VERSION "HSCAN2"

NS_ :

BS_:

BU_: FVCM Diagnostics GW EPS EHBS SCSABS Tester vector__xxx

BO_ 1947 DIAG_DTCInfo_FVCM: 7 FVCM
 SG_ DTCInfomationFVCMHSC2 : 7|56@0+ (1,0) [0|0] ""  vector__xxx

BO_ 1851 DIAG_PhysResp_FVCM: 8 FVCM
 SG_ DiagnosticRespFVCM : 7|64@0+ (1,0) [0|0] ""  Diagnostics

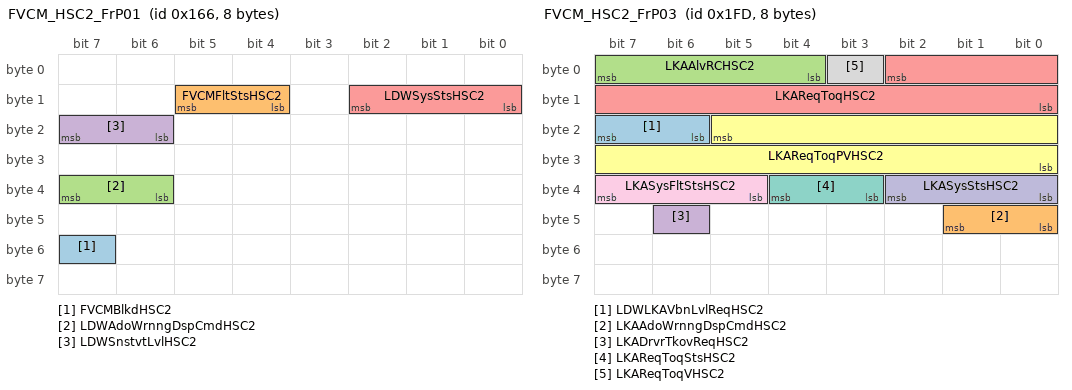
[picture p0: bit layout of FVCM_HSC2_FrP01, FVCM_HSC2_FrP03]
BO_ 358 FVCM_HSC2_FrP01: 8 FVCM
 SG_ FVCMBlkdHSC2 : 55|1@0+ (1,0) [0|1] ""  GW
 SG_ FVCMFltStsHSC2 : 13|2@0+ (1,0) [0|3] ""  GW,EPS
 SG_ LDWAdoWrnngDspCmdHSC2 : 39|2@0+ (1,0) [0|3] ""  GW
 SG_ LDWSnstvtLvlHSC2 : 23|2@0+ (1,0) [0|3] ""  GW
 SG_ LDWSysStsHSC2 : 10|3@0+ (1,0) [0|7] ""  GW

BO_ 359 FVCM_HSC2_FrP02: 8 FVCM
 SG_ AutoMainBeamLghtReqHSC2 : 15|2@0+ (1,0) [0|3] ""  GW
 SG_ DistSinceTrgtCamrHSC2 : 7|8@0+ (8.235,-100) [-100|1999.92] ""  GW
 SG_ FVCMCalPrgsReqHSC2 : 36|3@0+ (1,0) [0|7] ""  GW
 SG_ HandOffStrgWhlDetnStaHSC2 : 44|2@0+ (1,0) [0|3] ""  GW
 SG_ HandOffStrgWhlDetnStaVHSC2 : 45|1@0+ (1,0) [0|1] ""  GW
 SG_ LDWLKAAudReqHSC2 : 47|2@0+ (1,0) [0|3] ""  GW
 SG_ LDWLKADspCmdHSC2 : 50|3@0+ (1,0) [0|7] ""  GW
 SG_ LDWLKAHapticWrnngDspCmdHSC2 : 63|2@0+ (1,0) [0|3] ""  GW
 SG_ LDWLKALVsulznReqHSC2 : 53|3@0+ (1,0) [0|7] ""  GW
 SG_ LDWLKARVsulznReqHSC2 : 42|3@0+ (1,0) [0|7] ""  GW
 SG_ LDWSysFltStsHSC2 : 39|3@0+ (1,0) [0|7] ""  GW
 SG_ SpdAstCondStsCamrHSC2 : 11|4@0+ (1,0) [0|15] ""  GW
 SG_ SpdAstReqStsCamrHSC2 : 13|2@0+ (1,0) [0|3] ""  GW
 SG_ TJAICADspCmdHSC2 : 55|2@0+ (1,0) [0|3] ""  GW
 SG_ TJAICASysFltStsHSC2 : 61|3@0+ (1,0) [0|7] ""  GW,EPS
 SG_ TJAICASysStsHSC2 : 58|3@0+ (1,0) [0|7] ""  GW,EPS
 SG_ TrgtSpdReqCamrHSC2 : 22|15@0+ (0.015625,0) [0|511.984] ""  GW

BO_ 509 FVCM_HSC2_FrP03: 8 FVCM
 SG_ LDWLKAVbnLvlReqHSC2 : 23|2@0+ (1,0) [0|3] ""  GW,EPS
 SG_ LKAAdoWrnngDspCmdHSC2 : 41|2@0+ (1,0) [0|3] ""  vector__xxx
 SG_ LKAAlvRCHSC2 : 7|4@0+ (1,0) [0|15] ""  EPS
 SG_ LKADrvrTkovReqHSC2 : 46|1@0+ (1,0) [0|1] ""  GW
 SG_ LKAReqToqHSC2 : 2|11@0+ (0.01,-10.24) [-10.24|10.23] ""  EPS
 SG_ LKAReqToqPVHSC2 : 21|14@0+ (1,0) [0|16383] ""  EPS
 SG_ LKAReqToqStsHSC2 : 36|2@0+ (1,0) [0|3] ""  EPS
 SG_ LKAReqToqVHSC2 : 3|1@0+ (1,0) [0|1] ""  EPS
 SG_ LKASysFltStsHSC2 : 39|3@0+ (1,0) [0|7] ""  GW,EPS
 SG_ LKASysStsHSC2 : 34|3@0+ (1,0) [0|7] ""  GW,EPS

BO_ 2015 DIAG_FuncReq_HSC2: 8 Diagnostics
 SG_ DiagnosticFuncAddrReq_h2 : 7|64@0+ (1,0) [0|0] ""  FVCM

BO_ 1843 DIAG_PhysReq_FVCM: 8 Diagnostics
 SG_ DiagnosticReqFVCM_h2 : 7|64@0+ (1,0) [0|0] ""  FVCM

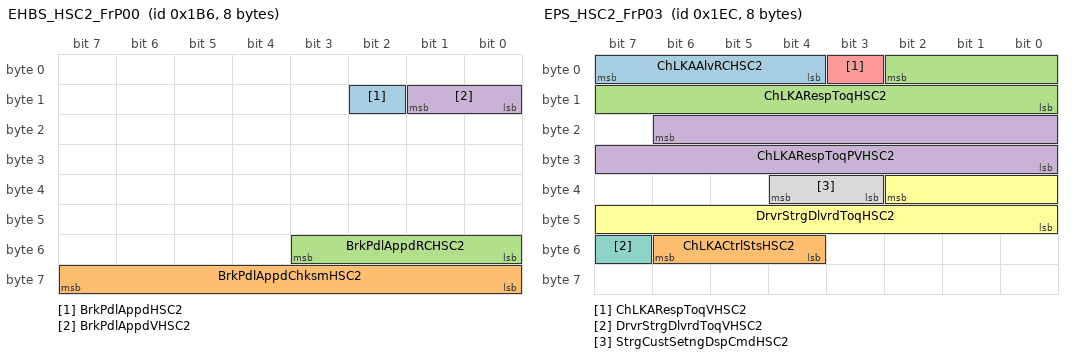
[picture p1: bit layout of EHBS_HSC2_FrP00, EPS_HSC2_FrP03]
BO_ 438 EHBS_HSC2_FrP00: 8 EHBS
 SG_ BrkPdlAppdHSC2 : 10|1@0+ (1,0) [0|1] ""  FVCM
 SG_ BrkPdlAppdChksmHSC2 : 63|8@0+ (1,0) [0|255] ""  FVCM
 SG_ BrkPdlAppdRCHSC2 : 51|4@0+ (1,0) [0|15] ""  FVCM
 SG_ BrkPdlAppdVHSC2 : 9|2@0+ (1,0) [0|3] ""  FVCM

BO_ 492 EPS_HSC2_FrP03: 8 EPS
 SG_ ChLKAAlvRCHSC2 : 7|4@0+ (1,0) [0|15] ""  FVCM
 SG_ ChLKACtrlStsHSC2 : 54|3@0+ (1,0) [0|7] ""  FVCM
 SG_ ChLKARespToqHSC2 : 2|11@0+ (0.01,-10.24) [-10.24|10.23] ""  FVCM
 SG_ ChLKARespToqPVHSC2 : 22|15@0+ (1,0) [0|32767] ""  FVCM
 SG_ ChLKARespToqVHSC2 : 3|1@0+ (1,0) [0|1] ""  FVCM
 SG_ DrvrStrgDlvrdToqHSC2 : 34|11@0+ (0.01,-10.24) [-10.24|10.23] ""  FVCM
 SG_ DrvrStrgDlvrdToqVHSC2 : 55|1@0+ (1,0) [0|1] ""  FVCM
 SG_ StrgCustSetngDspCmdHSC2 : 36|2@0+ (1,0) [0|3] ""  FVCM

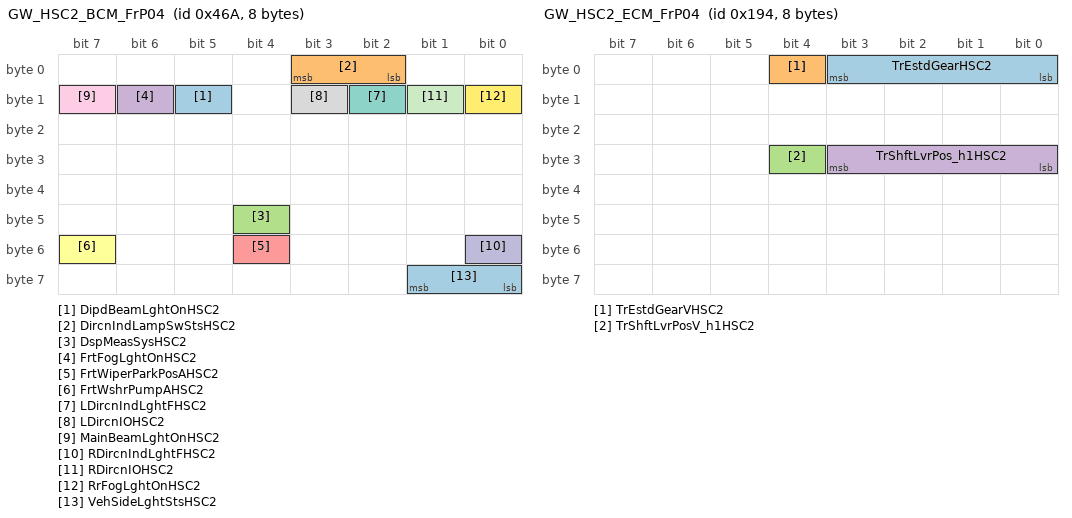
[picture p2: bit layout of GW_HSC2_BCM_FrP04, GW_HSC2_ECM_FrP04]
BO_ 1130 GW_HSC2_BCM_FrP04: 8 GW
 SG_ DipdBeamLghtOnHSC2 : 13|1@0+ (1,0) [0|1] ""  FVCM
 SG_ DircnIndLampSwStsHSC2 : 3|2@0+ (1,0) [0|3] ""  FVCM
 SG_ DspMeasSysHSC2 : 44|1@0+ (1,0) [0|1] ""  FVCM
 SG_ FrtFogLghtOnHSC2 : 14|1@0+ (1,0) [0|1] ""  FVCM
 SG_ FrtWiperParkPosAHSC2 : 52|1@0+ (1,0) [0|1] ""  FVCM
 SG_ FrtWshrPumpAHSC2 : 55|1@0+ (1,0) [0|1] ""  FVCM
 SG_ LDircnIndLghtFHSC2 : 10|1@0+ (1,0) [0|1] ""  FVCM
 SG_ LDircnIOHSC2 : 11|1@0+ (1,0) [0|1] ""  FVCM
 SG_ MainBeamLghtOnHSC2 : 15|1@0+ (1,0) [0|1] ""  FVCM
 SG_ RDircnIndLghtFHSC2 : 48|1@0+ (1,0) [0|1] ""  FVCM
 SG_ RDircnIOHSC2 : 9|1@0+ (1,0) [0|1] ""  FVCM
 SG_ RrFogLghtOnHSC2 : 8|1@0+ (1,0) [0|1] ""  FVCM
 SG_ VehSideLghtStsHSC2 : 57|2@0+ (1,0) [0|3] ""  FVCM

BO_ 540 GW_HSC2_BCM_FrP06: 8 GW
 SG_ ClstrDspdVehSpdHSC2 : 55|8@0+ (1,0) [0|254] ""  FVCM
 SG_ FrtWiperSwStsHSC2 : 47|2@0+ (1,0) [0|3] ""  FVCM

BO_ 498 GW_HSC2_BCM_FrP07: 2 GW
 SG_ SysBPMHSC2 : 5|2@0+ (1,0) [0|3] ""  FVCM
 SG_ SysBPMEnbdHSC2 : 6|1@0+ (1,0) [0|1] ""  FVCM

BO_ 404 GW_HSC2_ECM_FrP04: 8 GW
 SG_ TrEstdGearHSC2 : 3|4@0+ (1,0) [0|15] ""  FVCM
 SG_ TrEstdGearVHSC2 : 4|1@0+ (1,0) [0|1] ""  FVCM
 SG_ TrShftLvrPosV_h1HSC2 : 28|1@0+ (1,0) [0|1] ""  FVCM
 SG_ TrShftLvrPos_h1HSC2 : 27|4@0+ (1,0) [0|15] ""  FVCM

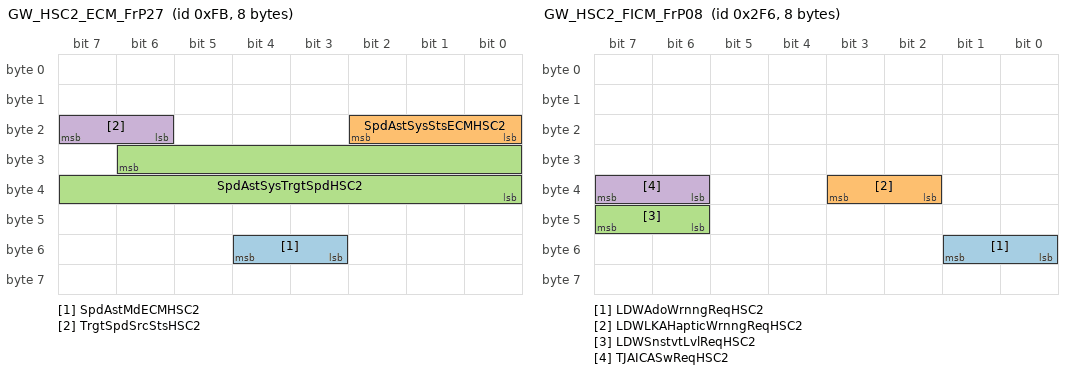
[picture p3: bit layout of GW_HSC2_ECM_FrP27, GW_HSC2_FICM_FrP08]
BO_ 251 GW_HSC2_ECM_FrP27: 8 GW
 SG_ SpdAstMdECMHSC2 : 52|2@0+ (1,0) [0|3] ""  FVCM
 SG_ SpdAstSysStsECMHSC2 : 18|3@0+ (1,0) [0|7] ""  FVCM
 SG_ SpdAstSysTrgtSpdHSC2 : 30|15@0+ (0.015625,0) [0|511.984] ""  FVCM
 SG_ TrgtSpdSrcStsHSC2 : 23|2@0+ (1,0) [0|3] ""  FVCM

BO_ 886 GW_HSC2_FICM_FrP02: 8 GW
 SG_ LDWLKASwReqHSC2 : 31|3@0+ (1,0) [0|7] ""  FVCM
 SG_ RstrFctryDeftsReqHSC2 : 56|1@0+ (1,0) [0|1] ""  FVCM

BO_ 758 GW_HSC2_FICM_FrP08: 8 GW
 SG_ LDWAdoWrnngReqHSC2 : 49|2@0+ (1,0) [0|3] ""  FVCM
 SG_ LDWLKAHapticWrnngReqHSC2 : 35|2@0+ (1,0) [0|3] ""  FVCM
 SG_ LDWSnstvtLvlReqHSC2 : 47|2@0+ (1,0) [0|3] ""  FVCM
 SG_ TJAICASwReqHSC2 : 39|2@0+ (1,0) [0|3] ""  FVCM

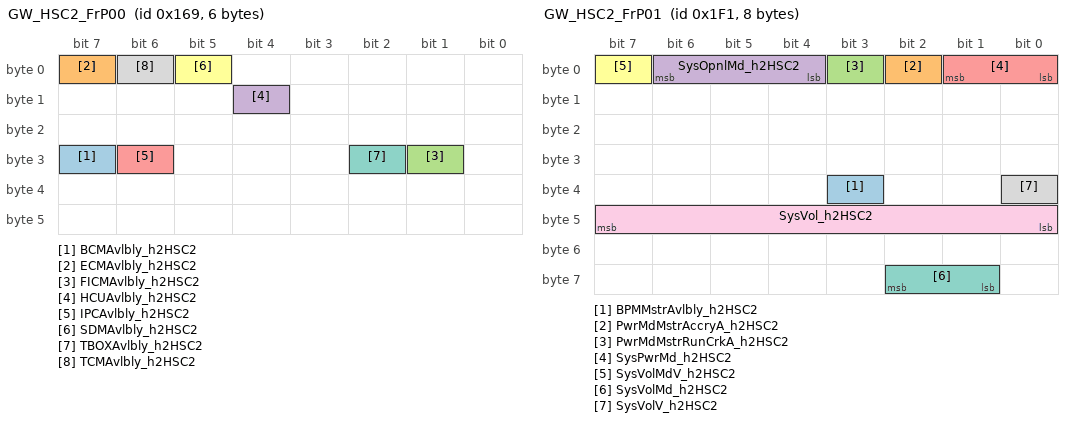
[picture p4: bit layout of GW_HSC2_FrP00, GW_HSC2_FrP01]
BO_ 361 GW_HSC2_FrP00: 6 GW
 SG_ BCMAvlbly_h2HSC2 : 31|1@0+ (1,0) [0|1] ""  FVCM
 SG_ ECMAvlbly_h2HSC2 : 7|1@0+ (1,0) [0|1] ""  FVCM
 SG_ FICMAvlbly_h2HSC2 : 25|1@0+ (1,0) [0|1] ""  FVCM
 SG_ HCUAvlbly_h2HSC2 : 12|1@0+ (1,0) [0|1] ""  FVCM
 SG_ IPCAvlbly_h2HSC2 : 30|1@0+ (1,0) [0|1] ""  FVCM
 SG_ SDMAvlbly_h2HSC2 : 5|1@0+ (1,0) [0|1] ""  FVCM
 SG_ TBOXAvlbly_h2HSC2 : 26|1@0+ (1,0) [0|1] ""  FVCM
 SG_ TCMAvlbly_h2HSC2 : 6|1@0+ (1,0) [0|1] ""  FVCM

BO_ 497 GW_HSC2_FrP01: 8 GW
 SG_ BPMMstrAvlbly_h2HSC2 : 35|1@0+ (1,0) [0|1] ""  FVCM
 SG_ PwrMdMstrAccryA_h2HSC2 : 2|1@0+ (1,0) [0|1] ""  FVCM
 SG_ PwrMdMstrRunCrkA_h2HSC2 : 3|1@0+ (1,0) [0|1] ""  FVCM
 SG_ SysOpnlMd_h2HSC2 : 6|3@0+ (1,0) [0|7] ""  FVCM
 SG_ SysPwrMd_h2HSC2 : 1|2@0+ (1,0) [0|3] ""  FVCM
 SG_ SysVolMdV_h2HSC2 : 7|1@0+ (1,0) [0|1] ""  FVCM
 SG_ SysVolMd_h2HSC2 : 58|2@0+ (1,0) [0|3] ""  FVCM
 SG_ SysVolV_h2HSC2 : 32|1@0+ (1,0) [0|1] ""  FVCM
 SG_ SysVol_h2HSC2 : 47|8@0+ (0.1,3) [3|28.5] ""  FVCM

BO_ 1344 GW_HSC2_FrP08: 8 GW
 SG_ VehOdoV_h2HSC2 : 31|1@0+ (1,0) [0|1] ""  FVCM
 SG_ VehOdo_h2HSC2 : 7|24@0+ (1,0) [0|16777200] ""  FVCM

BO_ 795 GW_HSC2_FrP09: 8 GW
 SG_ LKASwAHSC2 : 57|2@0+ (1,0) [0|3] ""  FVCM
 SG_ VehDrvngMd_h2HSC2 : 29|3@0+ (1,0) [0|7] ""  FVCM

BO_ 1009 GW_HSC2_FrP10: 8 GW
 SG_ OtsdAirTemCrValV_h2HSC2 : 48|1@0+ (1,0) [0|1] ""  FVCM
 SG_ OtsdAirTemCrVal_h2HSC2 : 63|8@0+ (0.5,-40) [-40|87.5] ""  FVCM

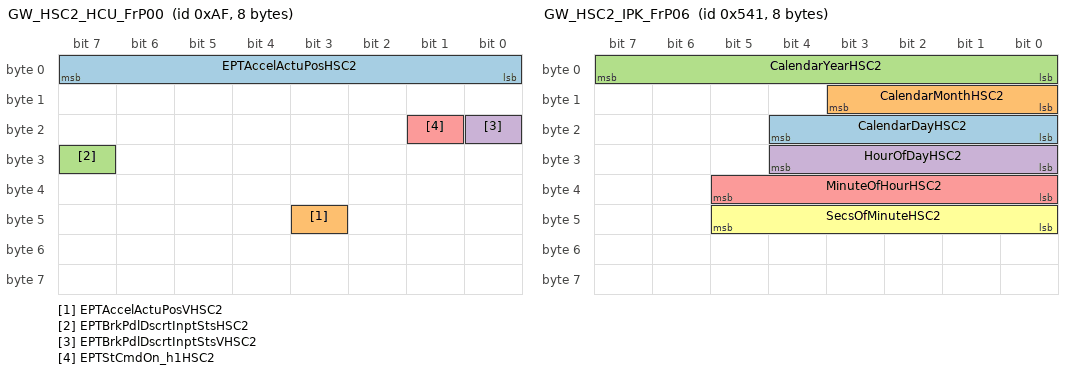
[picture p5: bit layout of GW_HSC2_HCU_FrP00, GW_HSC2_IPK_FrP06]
BO_ 175 GW_HSC2_HCU_FrP00: 8 GW
 SG_ EPTAccelActuPosHSC2 : 7|8@0+ (0.392157,0) [0|100] ""  FVCM
 SG_ EPTAccelActuPosVHSC2 : 43|1@0+ (1,0) [0|1] ""  FVCM
 SG_ EPTBrkPdlDscrtInptStsHSC2 : 31|1@0+ (1,0) [0|1] ""  FVCM
 SG_ EPTBrkPdlDscrtInptStsVHSC2 : 16|1@0+ (1,0) [0|1] ""  FVCM
 SG_ EPTStCmdOn_h1HSC2 : 17|1@0+ (1,0) [0|1] ""  FVCM

BO_ 406 GW_HSC2_HCU_FrP01: 8 GW
 SG_ EPTAccelEfctvPosHSC2 : 47|8@0+ (0.392157,0) [0|100] ""  FVCM
 SG_ EPTRdy_h1HSC2 : 38|1@0+ (1,0) [0|1] ""  FVCM

BO_ 172 GW_HSC2_HCU_FrP08: 8 GW
 SG_ SLIFStsHSC2 : 35|3@0+ (1,0) [0|7] ""  FVCM

BO_ 1345 GW_HSC2_IPK_FrP06: 8 GW
 SG_ CalendarDayHSC2 : 20|5@0+ (1,0) [0|31] ""  FVCM
 SG_ CalendarMonthHSC2 : 11|4@0+ (1,0) [0|15] ""  FVCM
 SG_ CalendarYearHSC2 : 7|8@0+ (1,2000) [2000|2255] ""  FVCM
 SG_ HourOfDayHSC2 : 28|5@0+ (1,0) [0|23] ""  FVCM
 SG_ MinuteOfHourHSC2 : 37|6@0+ (1,0) [0|59] ""  FVCM
 SG_ SecsOfMinuteHSC2 : 45|6@0+ (1,0) [0|59] ""  FVCM

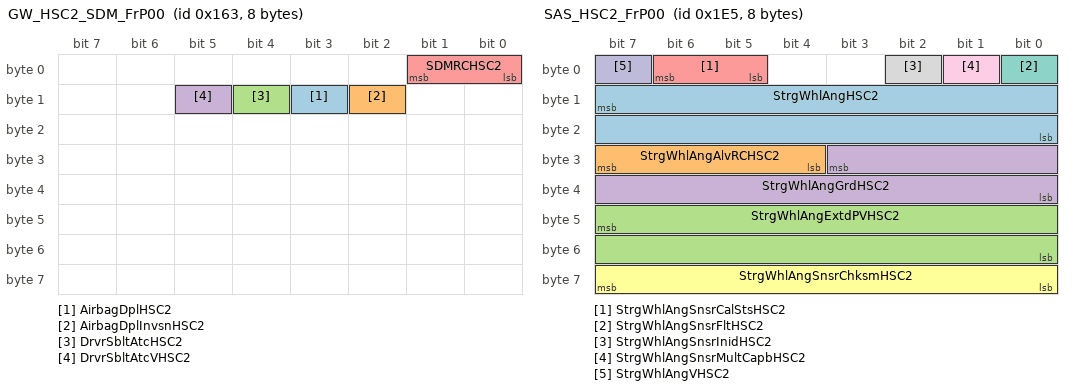
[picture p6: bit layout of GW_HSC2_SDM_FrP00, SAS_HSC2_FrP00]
BO_ 355 GW_HSC2_SDM_FrP00: 8 GW
 SG_ AirbagDplHSC2 : 11|1@0+ (1,0) [0|1] ""  FVCM
 SG_ AirbagDplInvsnHSC2 : 10|1@0+ (1,0) [0|1] ""  FVCM
 SG_ DrvrSbltAtcHSC2 : 12|1@0+ (1,0) [0|1] ""  FVCM
 SG_ DrvrSbltAtcVHSC2 : 13|1@0+ (1,0) [0|1] ""  FVCM
 SG_ SDMRCHSC2 : 1|2@0+ (1,0) [0|3] ""  FVCM

BO_ 485 SAS_HSC2_FrP00: 8 EPS
 SG_ StrgWhlAngHSC2 : 15|16@0+ (0.0625,-2048) [-2048|2047.88] ""  FVCM
 SG_ StrgWhlAngAlvRCHSC2 : 31|4@0+ (1,0) [0|15] ""  FVCM
 SG_ StrgWhlAngExtdPVHSC2 : 47|16@0+ (1,0) [0|65535] ""  FVCM
 SG_ StrgWhlAngGrdHSC2 : 27|12@0+ (1,-2048) [-2048|2046] ""  FVCM
 SG_ StrgWhlAngSnsrCalStsHSC2 : 6|2@0+ (1,0) [0|3] ""  FVCM
 SG_ StrgWhlAngSnsrChksmHSC2 : 63|8@0+ (1,0) [0|255] ""  FVCM
 SG_ StrgWhlAngSnsrFltHSC2 : 0|1@0+ (1,0) [0|1] ""  FVCM
 SG_ StrgWhlAngSnsrInidHSC2 : 2|1@0+ (1,0) [0|1] ""  FVCM
 SG_ StrgWhlAngSnsrMultCapbHSC2 : 1|1@0+ (1,0) [0|1] ""  FVCM
 SG_ StrgWhlAngVHSC2 : 7|1@0+ (1,0) [0|1] ""  FVCM

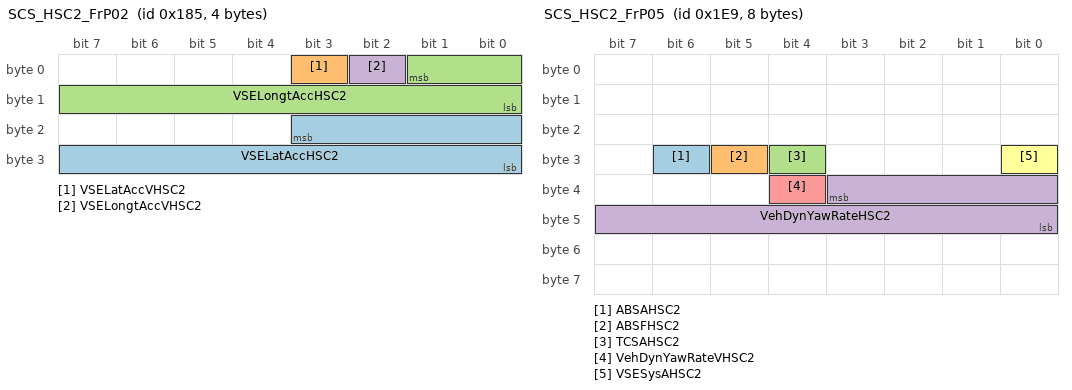
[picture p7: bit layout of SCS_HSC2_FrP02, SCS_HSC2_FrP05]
BO_ 389 SCS_HSC2_FrP02: 4 SCSABS
 SG_ VSELatAccHSC2 : 19|12@0- (0.015625,0) [-32|31.9844] ""  FVCM
 SG_ VSELatAccVHSC2 : 3|1@0+ (1,0) [0|1] ""  FVCM
 SG_ VSELongtAccHSC2 : 1|10@0- (0.03,0) [-15.36|15.33] ""  FVCM
 SG_ VSELongtAccVHSC2 : 2|1@0+ (1,0) [0|1] ""  FVCM

BO_ 455 SCS_HSC2_FrP03: 8 SCSABS
 SG_ LNonDrvnWhlRotlDircnHSC2 : 33|2@0+ (1,0) [0|3] ""  FVCM
 SG_ RNonDrvnWhlRotlDircnHSC2 : 35|2@0+ (1,0) [0|3] ""  FVCM

BO_ 489 SCS_HSC2_FrP05: 8 SCSABS
 SG_ ABSAHSC2 : 30|1@0+ (1,0) [0|1] ""  FVCM
 SG_ ABSFHSC2 : 29|1@0+ (1,0) [0|1] ""  FVCM
 SG_ TCSAHSC2 : 28|1@0+ (1,0) [0|1] ""  FVCM
 SG_ VehDynYawRateHSC2 : 35|12@0- (0.0625,0) [-128|127.938] ""  FVCM
 SG_ VehDynYawRateVHSC2 : 36|1@0+ (1,0) [0|1] ""  FVCM
 SG_ VSESysAHSC2 : 24|1@0+ (1,0) [0|1] ""  FVCM

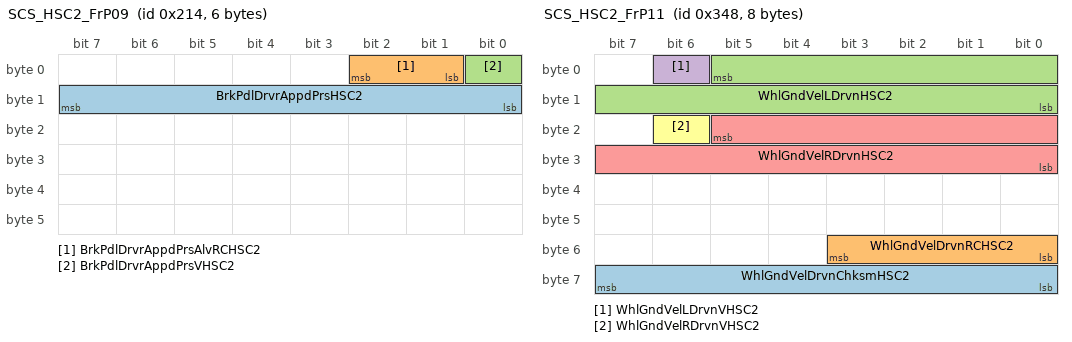
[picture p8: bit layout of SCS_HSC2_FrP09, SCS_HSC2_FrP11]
BO_ 532 SCS_HSC2_FrP09: 6 SCSABS
 SG_ BrkPdlDrvrAppdPrsHSC2 : 15|8@0+ (75,0) [0|19125] ""  FVCM
 SG_ BrkPdlDrvrAppdPrsAlvRCHSC2 : 2|2@0+ (1,0) [0|3] ""  FVCM
 SG_ BrkPdlDrvrAppdPrsVHSC2 : 0|1@0+ (1,0) [0|1] ""  FVCM

BO_ 840 SCS_HSC2_FrP11: 8 SCSABS
 SG_ WhlGndVelDrvnChksmHSC2 : 63|8@0+ (1,0) [0|255] ""  FVCM
 SG_ WhlGndVelDrvnRCHSC2 : 51|4@0+ (1,0) [0|15] ""  FVCM
 SG_ WhlGndVelLDrvnHSC2 : 5|14@0+ (0.03125,0) [0|511.969] ""  FVCM
 SG_ WhlGndVelLDrvnVHSC2 : 6|1@0+ (1,0) [0|1] ""  FVCM
 SG_ WhlGndVelRDrvnHSC2 : 21|14@0+ (0.03125,0) [0|511.969] ""  FVCM
 SG_ WhlGndVelRDrvnVHSC2 : 22|1@0+ (1,0) [0|1] ""  FVCM

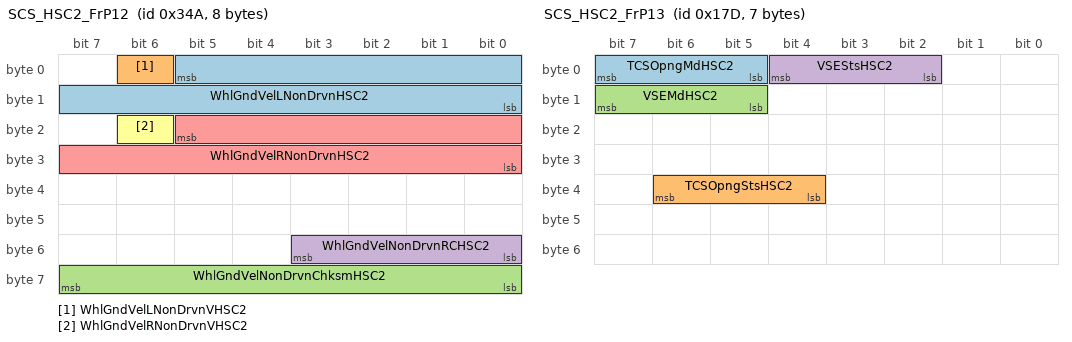
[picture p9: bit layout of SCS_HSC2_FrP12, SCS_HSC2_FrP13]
BO_ 842 SCS_HSC2_FrP12: 8 SCSABS
 SG_ WhlGndVelLNonDrvnHSC2 : 5|14@0+ (0.03125,0) [0|511.969] ""  FVCM
 SG_ WhlGndVelLNonDrvnVHSC2 : 6|1@0+ (1,0) [0|1] ""  FVCM
 SG_ WhlGndVelNonDrvnChksmHSC2 : 63|8@0+ (1,0) [0|255] ""  FVCM
 SG_ WhlGndVelNonDrvnRCHSC2 : 51|4@0+ (1,0) [0|15] ""  FVCM
 SG_ WhlGndVelRNonDrvnHSC2 : 21|14@0+ (0.03125,0) [0|511.969] ""  FVCM
 SG_ WhlGndVelRNonDrvnVHSC2 : 22|1@0+ (1,0) [0|1] ""  FVCM

BO_ 381 SCS_HSC2_FrP13: 7 SCSABS
 SG_ TCSOpngMdHSC2 : 7|3@0+ (1,0) [0|7] ""  FVCM
 SG_ TCSOpngStsHSC2 : 38|3@0+ (1,0) [0|7] ""  FVCM
 SG_ VSEMdHSC2 : 15|3@0+ (1,0) [0|7] ""  FVCM
 SG_ VSEStsHSC2 : 4|3@0+ (1,0) [0|7] ""  FVCM

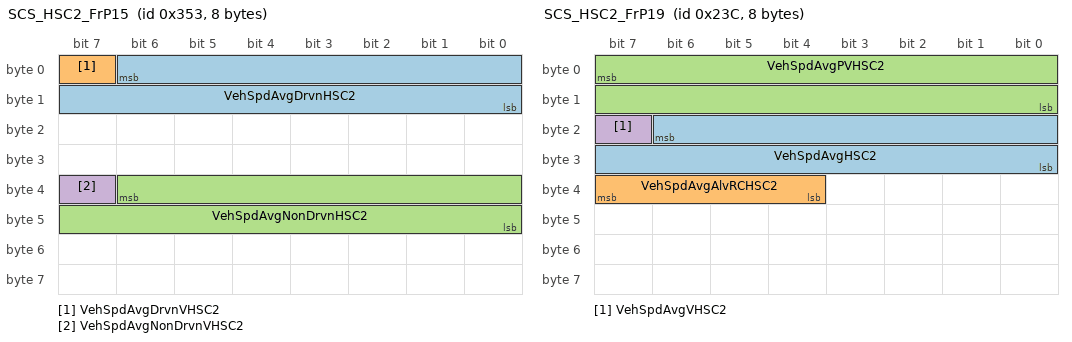
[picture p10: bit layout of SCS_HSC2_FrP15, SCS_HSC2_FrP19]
BO_ 851 SCS_HSC2_FrP15: 8 SCSABS
 SG_ VehSpdAvgDrvnHSC2 : 6|15@0+ (0.015625,0) [0|511.984] ""  FVCM
 SG_ VehSpdAvgDrvnVHSC2 : 7|1@0+ (1,0) [0|1] ""  FVCM
 SG_ VehSpdAvgNonDrvnHSC2 : 38|15@0+ (0.015625,0) [0|511.984] ""  FVCM
 SG_ VehSpdAvgNonDrvnVHSC2 : 39|1@0+ (1,0) [0|1] ""  FVCM

BO_ 572 SCS_HSC2_FrP19: 8 SCSABS
 SG_ VehSpdAvgHSC2 : 22|15@0+ (0.015625,0) [0|511.984] ""  FVCM
 SG_ VehSpdAvgAlvRCHSC2 : 39|4@0+ (1,0) [0|15] ""  FVCM
 SG_ VehSpdAvgPVHSC2 : 7|16@0+ (1,0) [0|65535] ""  FVCM
 SG_ VehSpdAvgVHSC2 : 23|1@0+ (1,0) [0|1] ""  FVCM

BO_ 588 SCS_HSC2_FrP22: 8 SCSABS
 SG_ LDrvnWhlRotlDircnHSC2 : 15|2@0+ (1,0) [0|3] ""  FVCM
 SG_ RDrvnWhlRotlDircnHSC2 : 2|2@0+ (1,0) [0|3] ""  FVCM

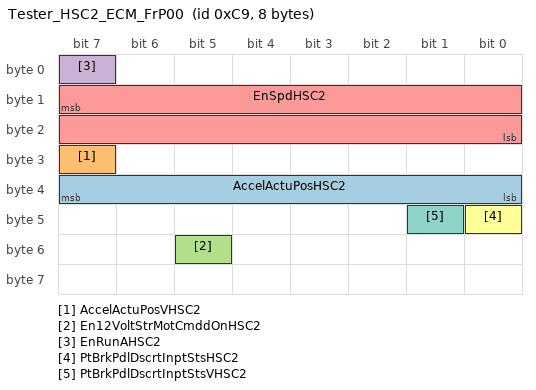
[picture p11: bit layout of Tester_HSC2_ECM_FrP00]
BO_ 201 Tester_HSC2_ECM_FrP00: 8 Tester
 SG_ AccelActuPosHSC2 : 39|8@0+ (0.392157,0) [0|100] ""  FVCM
 SG_ AccelActuPosVHSC2 : 31|1@0+ (1,0) [0|1] ""  FVCM
 SG_ En12VoltStrMotCmddOnHSC2 : 53|1@0+ (1,0) [0|1] ""  FVCM
 SG_ EnRunAHSC2 : 7|1@0+ (1,0) [0|1] ""  FVCM
 SG_ EnSpdHSC2 : 15|16@0+ (0.25,0) [0|16383.8] ""  FVCM
 SG_ PtBrkPdlDscrtInptStsHSC2 : 40|1@0+ (1,0) [0|1] ""  FVCM
 SG_ PtBrkPdlDscrtInptStsVHSC2 : 41|1@0+ (1,0) [0|1] ""  FVCM

BO_ 190 Tester_HSC2_ECM_FrP01: 3 Tester
 SG_ AccelEfctvPosHSC2 : 23|8@0+ (0.392157,0) [0|100] ""  FVCM

BO_ 471 Tester_HSC2_ECM_FrP07: 2 Tester
 SG_ EnASSStaHSC2 : 1|2@0+ (1,0) [0|3] ""  FVCM

CM_ SG_ 1947 DTCInfomationFVCMHSC2 "DTC Infomation of FVCM

The length of DTC information signal is 7 bytes.
Byte 0 is MSB (most significant byte), and Byte 6 is LSB (least significant byte).
For each byte, Bit 7 is msb (most significant bit), and Bit 0 is lsb (least significant bit).

Byte 0:
Bit (7-4): DTC Serious Level
Bit (3-0): Reserved

Byte 1:
Bit (7-0): Reserved

Byte 2:
Bit (7-0): DTCHighByte

Byte 3:
Bit (7-0): DTCLowByte

Byte 4:
Bit (7-0): DTCFailureTypeByte

Byte 5:
Bit 7: warningIndicatorRequested
Bit 6: testNotCompletedThisOperationCycle
Bit 5: testFailedSinceLastClear
Bit 4: testNotCompletedSinceLastClear
Bit 3: confirmedDTC
Bit 2: pendingDTC
Bit 1: testFailedThisOperationCycle
Bit 0: testFailed

Byte 6:
Bit (7-0): DTC Type

For more detail, please refer to SMTC 2 800 004.
";
CM_ SG_ 1851 DiagnosticRespFVCM "Diagnostic response from FVCM";
CM_ SG_ 358 LDWSnstvtLvlHSC2 "Lane Departure Warning Sensitivity Level";
CM_ SG_ 359 LDWLKADspCmdHSC2 "Lane Departure Warning Lane Keeping Assist Display Command
";
CM_ SG_ 359 LDWLKAHapticWrnngDspCmdHSC2 "Lane Departure Warning Lane Keeping Assist Haptic Warning Display Command";
CM_ SG_ 359 LDWLKALVsulznReqHSC2 "Lane Departure Warning Lane Keeping Assist Left Visualization Request
";
CM_ SG_ 359 LDWLKARVsulznReqHSC2 "Lane Departure Warning Lane Keeping Assist Right Visualization Request
";
CM_ SG_ 359 SpdAstCondStsCamrHSC2 "Speed Assist Condition Status Camera";
CM_ SG_ 359 TJAICADspCmdHSC2 "Traffic Jam Assist Integrated Cruise Assist Display Command";
CM_ SG_ 359 TJAICASysFltStsHSC2 "Traffic Jam Assist Integrated Cruise Assist Fault Status
";
CM_ SG_ 359 TJAICASysStsHSC2 "Traffic Jam Assist Integrated Cruise Assist System Status
";
CM_ SG_ 2015 DiagnosticFuncAddrReq_h2 "Diagnostic functional address request";
CM_ SG_ 1843 DiagnosticReqFVCM_h2 "Diagnostic request to FVCM";
CM_ SG_ 492 StrgCustSetngDspCmdHSC2 "Steering Customization Setting Display Command
";
CM_ SG_ 1130 FrtWiperParkPosAHSC2 "Front Wiper Park Position Active
Wiper Park Position for the Front wiper";
CM_ SG_ 1130 FrtWshrPumpAHSC2 "Front Washer Pump Active";
CM_ SG_ 540 FrtWiperSwStsHSC2 "Front Wiper Switch Status";
CM_ SG_ 886 LDWLKASwReqHSC2 "Lane Departure Warning Lane Keeping Assist Switch Request";
CM_ SG_ 758 LDWLKAHapticWrnngReqHSC2 "Lane Departure Warning Lane Keeping Assist Haptic Warning Request";
CM_ SG_ 758 TJAICASwReqHSC2 "Traffic Jam Assist Integrated Cruise Assist Switch Request";
CM_ SG_ 361 HCUAvlbly_h2HSC2 "HCU Available

Detect if specific ECU is available according to node missing strategy by gateway ECU.

";
CM_ SG_ 795 LKASwAHSC2 "Lane Keeping Assist Switch Active";
CM_ SG_ 795 VehDrvngMd_h2HSC2 "Vehicle Driving Mode";
CM_ SG_ 175 EPTBrkPdlDscrtInptStsVHSC2 "Electric Powertrain Brake Pedal Discrete Input Status Validity";
CM_ SG_ 355 AirbagDplInvsnHSC2 "Airbag Deployed Inversion";
CM_ SG_ 840 WhlGndVelLDrvnVHSC2 "Wheel Ground Velocity Left Driven Validity";
CM_ SG_ 840 WhlGndVelRDrvnVHSC2 "Wheel Ground Velocity Right Driven Validity";
CM_ SG_ 842 WhlGndVelLNonDrvnVHSC2 "Wheel Ground Velocity Left Non Driven Validity";
CM_ SG_ 842 WhlGndVelRNonDrvnVHSC2 "Wheel Ground Velocity Right  Non Driven Validity";
BA_DEF_  "BaudRate" FLOAT 1000 1000000;
BA_DEF_ SG_  "GenSigLongName" STRING ;
BA_DEF_ BO_  "GenMsgSendType" ENUM  "cyclic","spontaneous","cyclicIfActive","spontaneousWithDelay","OnChangeWithRepetition","Immediate";
BA_DEF_ BO_  "GenMsgCycleTime" FLOAT 0 300000;
BA_DEF_ SG_  "GenSigStartValue" INT -9.22337203685478E+018 1.84467440737096E+019;
BA_DEF_DEF_  "BaudRate" 1000;
BA_DEF_DEF_  "GenSigLongName" "";
BA_DEF_DEF_  "GenMsgSendType" "";
BA_DEF_DEF_  "GenMsgCycleTime" 0;
BA_DEF_DEF_  "GenSigStartValue" 0;
BA_ "BaudRate" 500000;
BA_ "GenMsgSendType" BO_ 1947 1;
BA_ "GenMsgSendType" BO_ 1851 5;
BA_ "GenMsgCycleTime" BO_ 358 20;
BA_ "GenMsgSendType" BO_ 358 0;
BA_ "GenMsgCycleTime" BO_ 359 20;
BA_ "GenMsgSendType" BO_ 359 0;
BA_ "GenMsgCycleTime" BO_ 509 20;
BA_ "GenMsgSendType" BO_ 509 0;
BA_ "GenMsgSendType" BO_ 2015 5;
BA_ "GenMsgSendType" BO_ 1843 5;
BA_ "GenMsgCycleTime" BO_ 438 20;
BA_ "GenMsgSendType" BO_ 438 0;
BA_ "GenMsgCycleTime" BO_ 492 20;
BA_ "GenMsgSendType" BO_ 492 0;
BA_ "GenMsgCycleTime" BO_ 1130 50;
BA_ "GenMsgSendType" BO_ 1130 0;
BA_ "GenMsgCycleTime" BO_ 540 50;
BA_ "GenMsgSendType" BO_ 540 0;
BA_ "GenMsgCycleTime" BO_ 498 20;
BA_ "GenMsgSendType" BO_ 498 0;
BA_ "GenMsgCycleTime" BO_ 404 20;
BA_ "GenMsgSendType" BO_ 404 0;
BA_ "GenMsgCycleTime" BO_ 251 10;
BA_ "GenMsgSendType" BO_ 251 0;
BA_ "GenMsgCycleTime" BO_ 886 100;
BA_ "GenMsgSendType" BO_ 886 0;
BA_ "GenMsgCycleTime" BO_ 758 50;
BA_ "GenMsgSendType" BO_ 758 0;
BA_ "GenMsgCycleTime" BO_ 361 20;
BA_ "GenMsgSendType" BO_ 361 0;
BA_ "GenMsgCycleTime" BO_ 497 20;
BA_ "GenMsgSendType" BO_ 497 0;
BA_ "GenMsgCycleTime" BO_ 1344 1000;
BA_ "GenMsgSendType" BO_ 1344 0;
BA_ "GenMsgCycleTime" BO_ 795 100;
BA_ "GenMsgSendType" BO_ 795 0;
BA_ "GenMsgCycleTime" BO_ 1009 250;
BA_ "GenMsgSendType" BO_ 1009 0;
BA_ "GenMsgCycleTime" BO_ 175 10;
BA_ "GenMsgSendType" BO_ 175 0;
BA_ "GenMsgCycleTime" BO_ 406 20;
BA_ "GenMsgSendType" BO_ 406 0;
BA_ "GenMsgCycleTime" BO_ 172 10;
BA_ "GenMsgSendType" BO_ 172 0;
BA_ "GenMsgCycleTime" BO_ 1345 200;
BA_ "GenMsgSendType" BO_ 1345 0;
BA_ "GenMsgCycleTime" BO_ 355 20;
BA_ "GenMsgSendType" BO_ 355 0;
BA_ "GenMsgCycleTime" BO_ 485 10;
BA_ "GenMsgSendType" BO_ 485 0;
BA_ "GenMsgCycleTime" BO_ 389 20;
BA_ "GenMsgSendType" BO_ 389 0;
BA_ "GenMsgCycleTime" BO_ 455 10;
BA_ "GenMsgSendType" BO_ 455 0;
BA_ "GenMsgCycleTime" BO_ 489 10;
BA_ "GenMsgSendType" BO_ 489 0;
BA_ "GenMsgCycleTime" BO_ 532 50;
BA_ "GenMsgSendType" BO_ 532 0;
BA_ "GenMsgCycleTime" BO_ 840 50;
BA_ "GenMsgSendType" BO_ 840 0;
BA_ "GenMsgCycleTime" BO_ 842 50;
BA_ "GenMsgSendType" BO_ 842 0;
BA_ "GenMsgCycleTime" BO_ 381 100;
BA_ "GenMsgSendType" BO_ 381 0;
BA_ "GenMsgCycleTime" BO_ 851 100;
BA_ "GenMsgSendType" BO_ 851 0;
BA_ "GenMsgCycleTime" BO_ 572 20;
BA_ "GenMsgSendType" BO_ 572 0;
BA_ "GenMsgCycleTime" BO_ 588 20;
BA_ "GenMsgSendType" BO_ 588 0;
BA_ "GenMsgCycleTime" BO_ 201 10;
BA_ "GenMsgSendType" BO_ 201 0;
BA_ "GenMsgCycleTime" BO_ 190 10;
BA_ "GenMsgSendType" BO_ 190 0;
BA_ "GenMsgCycleTime" BO_ 471 25;
BA_ "GenMsgSendType" BO_ 471 0;
BA_ "GenSigLongName" SG_ 358 FVCMBlkdHSC2 "Front View Camera Module Blocked";
BA_ "GenSigLongName" SG_ 358 FVCMFltStsHSC2 "Front View Camera Module Fault Status";
BA_ "GenSigLongName" SG_ 358 LDWAdoWrnngDspCmdHSC2 "Lane Departure Warning Audio Warning Display Command";
BA_ "GenSigStartValue" SG_ 358 LDWAdoWrnngDspCmdHSC2 2;
BA_ "GenSigStartValue" SG_ 358 LDWSnstvtLvlHSC2 2;
BA_ "GenSigLongName" SG_ 358 LDWSysStsHSC2 "Lane Departure Warning System Status";
BA_ "GenSigLongName" SG_ 359 AutoMainBeamLghtReqHSC2 "Auto Main Beam Light Request";
BA_ "GenSigLongName" SG_ 359 DistSinceTrgtCamrHSC2 "Distance Since Target Camera";
BA_ "GenSigLongName" SG_ 359 FVCMCalPrgsReqHSC2 "FVCM Calibration Progress Request";
BA_ "GenSigLongName" SG_ 359 HandOffStrgWhlDetnStaHSC2 "Hand Off Steering Wheel Detection State";
BA_ "GenSigStartValue" SG_ 359 HandOffStrgWhlDetnStaHSC2 1;
BA_ "GenSigLongName" SG_ 359 HandOffStrgWhlDetnStaVHSC2 "Hand Off Steering Wheel Detection State Validity";
BA_ "GenSigLongName" SG_ 359 LDWLKAAudReqHSC2 "Lane Departure Warning Lane Keeping Assist Audible Request";
BA_ "GenSigLongName" SG_ 359 LDWLKADspCmdHSC2 "Lane Departure Warning Lane Keeping Assist Display Command";
BA_ "GenSigStartValue" SG_ 359 LDWLKADspCmdHSC2 1;
BA_ "GenSigLongName" SG_ 359 LDWLKAHapticWrnngDspCmdHSC2 "Lane Departure Warning Lane Keeping Assist Haptic Warning Display Command";
BA_ "GenSigStartValue" SG_ 359 LDWLKAHapticWrnngDspCmdHSC2 2;
BA_ "GenSigLongName" SG_ 359 LDWLKALVsulznReqHSC2 "Lane Departure Warning Lane Keeping Assist Left Visualization Request";
BA_ "GenSigLongName" SG_ 359 LDWLKARVsulznReqHSC2 "Lane Departure Warning Lane Keeping Assist Right Visualization Request";
BA_ "GenSigLongName" SG_ 359 LDWSysFltStsHSC2 "Lane Departure Warning System Fault Status";
BA_ "GenSigLongName" SG_ 359 SpdAstReqStsCamrHSC2 "Speed Assist Request Status Camera";
BA_ "GenSigStartValue" SG_ 359 SpdAstReqStsCamrHSC2 1;
BA_ "GenSigLongName" SG_ 359 TJAICADspCmdHSC2 "Traffic Jam Assist Integrated Cruise Assist Display Command";
BA_ "GenSigStartValue" SG_ 359 TJAICADspCmdHSC2 1;
BA_ "GenSigLongName" SG_ 359 TJAICASysFltStsHSC2 "Traffic Jam Assist Integrated Cruise Assist Fault Status";
BA_ "GenSigLongName" SG_ 359 TJAICASysStsHSC2 "Traffic Jam Assist Integrated Cruise Assist System Status";
BA_ "GenSigLongName" SG_ 359 TrgtSpdReqCamrHSC2 "Target Speed Request Camera";
BA_ "GenSigLongName" SG_ 509 LDWLKAVbnLvlReqHSC2 "Lane Departure Warning Lane Keeping Assist Vibration Level Request";
BA_ "GenSigLongName" SG_ 509 LKAAdoWrnngDspCmdHSC2 "Lane Keeping Assist Audio Warning Display Command";
BA_ "GenSigLongName" SG_ 509 LKAAlvRCHSC2 "Lane Keeping Assist Alive Rolling Count";
BA_ "GenSigLongName" SG_ 509 LKADrvrTkovReqHSC2 "Lane Keeping Assist Driver Takeover Request";
BA_ "GenSigLongName" SG_ 509 LKAReqToqHSC2 "Lane Keeping Assist Request Torque";
BA_ "GenSigStartValue" SG_ 509 LKAReqToqHSC2 1024;
BA_ "GenSigLongName" SG_ 509 LKAReqToqPVHSC2 "Lane Keeping Assist Request Torque Protection Value";
BA_ "GenSigLongName" SG_ 509 LKAReqToqStsHSC2 "Lane Keeping Assist Torque Request Status";
BA_ "GenSigLongName" SG_ 509 LKAReqToqVHSC2 "Lane Keeping Assist Request Torque Validity";
BA_ "GenSigLongName" SG_ 509 LKASysFltStsHSC2 "Lane Keeping Assist System Fault Status";
BA_ "GenSigLongName" SG_ 438 BrkPdlAppdHSC2 "Brake Pedal Applied";
BA_ "GenSigLongName" SG_ 438 BrkPdlAppdVHSC2 "Brake Pedal Applied Validity ";
BA_ "GenSigLongName" SG_ 492 ChLKAAlvRCHSC2 "Chassis Lane Keeping Assist Alive Rolling Count";
BA_ "GenSigLongName" SG_ 492 ChLKACtrlStsHSC2 "Chassis Lane Keeping Assist Control Status";
BA_ "GenSigLongName" SG_ 492 ChLKARespToqHSC2 "Chassis Lane Keeping Assist Response Torque";
BA_ "GenSigStartValue" SG_ 492 ChLKARespToqHSC2 1024;
BA_ "GenSigLongName" SG_ 492 ChLKARespToqVHSC2 "Chassis Lane Keeping Assist Response Torque Validity";
BA_ "GenSigLongName" SG_ 492 DrvrStrgDlvrdToqHSC2 "Driver Steering Delivered Torque";
BA_ "GenSigStartValue" SG_ 492 DrvrStrgDlvrdToqHSC2 1024;
BA_ "GenSigLongName" SG_ 492 DrvrStrgDlvrdToqVHSC2 "Driver Steering Delivered Torque Validity";
BA_ "GenSigLongName" SG_ 492 StrgCustSetngDspCmdHSC2 "Steering Customization Setting Display Command";
BA_ "GenSigStartValue" SG_ 492 StrgCustSetngDspCmdHSC2 2;
BA_ "GenSigLongName" SG_ 1130 DipdBeamLghtOnHSC2 "Dipped Beam Light On";
BA_ "GenSigLongName" SG_ 1130 DircnIndLampSwStsHSC2 "Direction Indication Lamp Switch Status";
BA_ "GenSigLongName" SG_ 1130 DspMeasSysHSC2 "Display Measurement System";
BA_ "GenSigLongName" SG_ 1130 FrtFogLghtOnHSC2 "Front Fog Light On";
BA_ "GenSigLongName" SG_ 1130 LDircnIndLghtFHSC2 "Left Direction Indication Light Failed";
BA_ "GenSigLongName" SG_ 1130 LDircnIOHSC2 "Left Direction Indication On";
BA_ "GenSigLongName" SG_ 1130 MainBeamLghtOnHSC2 "Main Beam Light On";
BA_ "GenSigLongName" SG_ 1130 RDircnIndLghtFHSC2 "Right Direction Indication Light Failed";
BA_ "GenSigLongName" SG_ 1130 RDircnIOHSC2 "Right Direction Indication On";
BA_ "GenSigLongName" SG_ 1130 RrFogLghtOnHSC2 "Rear Fog Light On";
BA_ "GenSigLongName" SG_ 1130 VehSideLghtStsHSC2 "Vehicle Side Light Status";
BA_ "GenSigLongName" SG_ 540 ClstrDspdVehSpdHSC2 "Cluster Displayed Vehicle Speed";
BA_ "GenSigLongName" SG_ 498 SysBPMHSC2 "System Backup Power Mode";
BA_ "GenSigLongName" SG_ 498 SysBPMEnbdHSC2 "System Backup Power Mode Enabled";
BA_ "GenSigLongName" SG_ 404 TrEstdGearHSC2 "Transmission Estimated Gear";
BA_ "GenSigLongName" SG_ 404 TrEstdGearVHSC2 "Transmission Estimated Gear Validity";
BA_ "GenSigLongName" SG_ 404 TrShftLvrPosV_h1HSC2 "Transmission Shift Lever Position Validity";
BA_ "GenSigLongName" SG_ 404 TrShftLvrPos_h1HSC2 "Transmission Shift Lever Position";
BA_ "GenSigLongName" SG_ 251 SpdAstMdECMHSC2 "Speed Assist Mode Engine Control Module";
BA_ "GenSigLongName" SG_ 251 SpdAstSysStsECMHSC2 "Speed Assist System Status Engine Control Module";
BA_ "GenSigLongName" SG_ 251 SpdAstSysTrgtSpdHSC2 "Speed Assist System Target Speed";
BA_ "GenSigLongName" SG_ 251 TrgtSpdSrcStsHSC2 "Target Speed Source Status";
BA_ "GenSigLongName" SG_ 886 RstrFctryDeftsReqHSC2 "Restore Factory Defaults Request";
BA_ "GenSigLongName" SG_ 758 LDWAdoWrnngReqHSC2 "Lane Departure Warning Audio Warning Request";
BA_ "GenSigLongName" SG_ 758 LDWSnstvtLvlReqHSC2 "Lane Departure Warning Sensitivity Level Request";
BA_ "GenSigLongName" SG_ 361 BCMAvlbly_h2HSC2 "Body Control Module Availability";
BA_ "GenSigLongName" SG_ 361 ECMAvlbly_h2HSC2 "Engine Control Module Availability";
BA_ "GenSigLongName" SG_ 361 FICMAvlbly_h2HSC2 "Front Infotainment Control Module Availability";
BA_ "GenSigLongName" SG_ 361 IPCAvlbly_h2HSC2 "Instrument Cluster Availability";
BA_ "GenSigLongName" SG_ 361 SDMAvlbly_h2HSC2 "Sensing Diagnostic Module Availability";
BA_ "GenSigLongName" SG_ 361 TBOXAvlbly_h2HSC2 "Telematics Box Availability";
BA_ "GenSigLongName" SG_ 361 TCMAvlbly_h2HSC2 "Transmission Control Module Availability";
BA_ "GenSigLongName" SG_ 497 BPMMstrAvlbly_h2HSC2 "Backup Power Mode Master Availability";
BA_ "GenSigLongName" SG_ 497 PwrMdMstrAccryA_h2HSC2 "Power Mode Master Accessory Active";
BA_ "GenSigLongName" SG_ 497 PwrMdMstrRunCrkA_h2HSC2 "Power Mode Master Run Crank Active";
BA_ "GenSigLongName" SG_ 497 SysOpnlMd_h2HSC2 "System Operational Mode";
BA_ "GenSigLongName" SG_ 497 SysPwrMd_h2HSC2 "System Power Mode";
BA_ "GenSigLongName" SG_ 497 SysVolMdV_h2HSC2 "System Voltage Mode Validity";
BA_ "GenSigLongName" SG_ 497 SysVolMd_h2HSC2 "System Voltage Mode";
BA_ "GenSigLongName" SG_ 497 SysVolV_h2HSC2 "System Voltage Validity";
BA_ "GenSigLongName" SG_ 497 SysVol_h2HSC2 "System Voltage";
BA_ "GenSigLongName" SG_ 1344 VehOdoV_h2HSC2 "Vehicle Odometer Validity";
BA_ "GenSigLongName" SG_ 1344 VehOdo_h2HSC2 "Vehicle Odometer";
BA_ "GenSigLongName" SG_ 795 VehDrvngMd_h2HSC2 "Vehicle Driving Mode";
BA_ "GenSigLongName" SG_ 1009 OtsdAirTemCrValV_h2HSC2 "Outside Air Temperature Corrected Value Validity";
BA_ "GenSigLongName" SG_ 1009 OtsdAirTemCrVal_h2HSC2 "Outside Air Temperature Corrected Value";
BA_ "GenSigLongName" SG_ 175 EPTAccelActuPosHSC2 "Electric Powertrain Accelerator Actual Position";
BA_ "GenSigLongName" SG_ 175 EPTAccelActuPosVHSC2 "Electric Powertrain Accelerator Actual Position Validity";
BA_ "GenSigLongName" SG_ 175 EPTBrkPdlDscrtInptStsHSC2 "Electric Powertrain Brake Pedal Discrete Input Status";
BA_ "GenSigStartValue" SG_ 175 EPTBrkPdlDscrtInptStsVHSC2 1;
BA_ "GenSigLongName" SG_ 175 EPTStCmdOn_h1HSC2 "Electric Powertrain Start Command On";
BA_ "GenSigLongName" SG_ 406 EPTAccelEfctvPosHSC2 "Electric Powertrain Accelerator Effective Position";
BA_ "GenSigLongName" SG_ 406 EPTRdy_h1HSC2 "Electric Powertrain Ready";
BA_ "GenSigLongName" SG_ 172 SLIFStsHSC2 "Speed Limit Information Function Status";
BA_ "GenSigLongName" SG_ 1345 CalendarDayHSC2 "Calendar Day";
BA_ "GenSigLongName" SG_ 1345 CalendarMonthHSC2 "Calendar Month";
BA_ "GenSigLongName" SG_ 1345 CalendarYearHSC2 "Calendar Year";
BA_ "GenSigLongName" SG_ 1345 HourOfDayHSC2 "Hour Of Day";
BA_ "GenSigLongName" SG_ 1345 MinuteOfHourHSC2 "Minute Of Hour";
BA_ "GenSigLongName" SG_ 1345 SecsOfMinuteHSC2 "Seconds Of Minute";
BA_ "GenSigLongName" SG_ 355 AirbagDplHSC2 "Airbag Deployed";
BA_ "GenSigStartValue" SG_ 355 AirbagDplInvsnHSC2 1;
BA_ "GenSigLongName" SG_ 355 DrvrSbltAtcHSC2 "Driver Seatbelt Attached";
BA_ "GenSigLongName" SG_ 355 DrvrSbltAtcVHSC2 "Driver Seatbelt Attached Validity";
BA_ "GenSigLongName" SG_ 355 SDMRCHSC2 "Sensing Diagnostic Module Rolling Count";
BA_ "GenSigLongName" SG_ 485 StrgWhlAngHSC2 "Steering Wheel Angle";
BA_ "GenSigLongName" SG_ 485 StrgWhlAngAlvRCHSC2 "Steering Wheel Angle Alive Rolling Count";
BA_ "GenSigLongName" SG_ 485 StrgWhlAngExtdPVHSC2 "Steering Wheel Angle Extended Protection Value";
BA_ "GenSigLongName" SG_ 485 StrgWhlAngGrdHSC2 "Steering Wheel Angle Gradient";
BA_ "GenSigLongName" SG_ 485 StrgWhlAngSnsrCalStsHSC2 "Steering Wheel Angle Sensor Calibration Status";
BA_ "GenSigLongName" SG_ 485 StrgWhlAngSnsrChksmHSC2 "Steering Wheel Angle Sensor Checksum";
BA_ "GenSigLongName" SG_ 485 StrgWhlAngSnsrFltHSC2 "Steering Wheel Angle Sensor Fault";
BA_ "GenSigLongName" SG_ 485 StrgWhlAngSnsrInidHSC2 "Steering Wheel Angle Sensor Initialized";
BA_ "GenSigLongName" SG_ 485 StrgWhlAngSnsrMultCapbHSC2 "Steering Wheel Angle Sensor Multiturn Capable";
BA_ "GenSigLongName" SG_ 485 StrgWhlAngVHSC2 "Steering Wheel Angle Validity";
BA_ "GenSigLongName" SG_ 389 VSELatAccHSC2 "Vehicle Stability Enhancement Lateral Acceleration";
BA_ "GenSigLongName" SG_ 389 VSELatAccVHSC2 "Vehicle Stability Enhancement Lateral Acceleration Validity";
BA_ "GenSigLongName" SG_ 389 VSELongtAccHSC2 "Vehicle Stability Enhancement Longitudinal Acceleration";
BA_ "GenSigLongName" SG_ 389 VSELongtAccVHSC2 "Vehicle Stability Enhancement Longitudinal Acceleration Validity";
BA_ "GenSigLongName" SG_ 455 LNonDrvnWhlRotlDircnHSC2 "Left Non Driven Wheel Rotational Direction";
BA_ "GenSigLongName" SG_ 455 RNonDrvnWhlRotlDircnHSC2 "Right Non Driven Wheel Rotational Direction";
BA_ "GenSigLongName" SG_ 489 ABSAHSC2 "Antilock Brake System Active";
BA_ "GenSigLongName" SG_ 489 ABSFHSC2 "Antilock Brake System Failed";
BA_ "GenSigLongName" SG_ 489 TCSAHSC2 "Traction Control System Active";
BA_ "GenSigLongName" SG_ 489 VehDynYawRateHSC2 "Vehicle Dynamics Yaw Rate";
BA_ "GenSigLongName" SG_ 489 VehDynYawRateVHSC2 "Vehicle Dynamics Yaw Rate Validity";
BA_ "GenSigLongName" SG_ 489 VSESysAHSC2 "Vehicle Stability Enhancement System Active";
BA_ "GenSigLongName" SG_ 532 BrkPdlDrvrAppdPrsHSC2 "Brake Pedal Driver Applied Pressure";
BA_ "GenSigLongName" SG_ 532 BrkPdlDrvrAppdPrsAlvRCHSC2 "Brake Pedal Driver Applied Pressure Alive Rolling Count";
BA_ "GenSigLongName" SG_ 532 BrkPdlDrvrAppdPrsVHSC2 "Brake Pedal Driver Applied Pressure Validity";
BA_ "GenSigLongName" SG_ 840 WhlGndVelDrvnChksmHSC2 "Wheel Ground Velocity Driven Checksum";
BA_ "GenSigLongName" SG_ 840 WhlGndVelDrvnRCHSC2 "Wheel Ground Velocity Driven Rolling Count";
BA_ "GenSigLongName" SG_ 840 WhlGndVelLDrvnHSC2 "Wheel Ground Velocity Left Driven";
BA_ "GenSigStartValue" SG_ 840 WhlGndVelLDrvnVHSC2 1;
BA_ "GenSigLongName" SG_ 840 WhlGndVelRDrvnHSC2 "Wheel Ground Velocity Right Driven";
BA_ "GenSigStartValue" SG_ 840 WhlGndVelRDrvnVHSC2 1;
BA_ "GenSigLongName" SG_ 842 WhlGndVelLNonDrvnHSC2 "Wheel Ground Velocity Left Non Driven";
BA_ "GenSigStartValue" SG_ 842 WhlGndVelLNonDrvnVHSC2 1;
BA_ "GenSigLongName" SG_ 842 WhlGndVelNonDrvnChksmHSC2 "Wheel Ground Velocity Non Driven Checksum";
BA_ "GenSigLongName" SG_ 842 WhlGndVelNonDrvnRCHSC2 "Wheel Ground Velocity Non Driven Rolling Count";
BA_ "GenSigLongName" SG_ 842 WhlGndVelRNonDrvnHSC2 "Wheel Ground Velocity Right Non Driven";
BA_ "GenSigLongName" SG_ 842 WhlGndVelRNonDrvnVHSC2 "Wheel Ground Velocity Right Non Driven Validity";
BA_ "GenSigStartValue" SG_ 842 WhlGndVelRNonDrvnVHSC2 1;
BA_ "GenSigLongName" SG_ 381 TCSOpngMdHSC2 "Traction Control System Operating Mode";
BA_ "GenSigLongName" SG_ 381 TCSOpngStsHSC2 "Traction Control System Operating Status";
BA_ "GenSigLongName" SG_ 381 VSEMdHSC2 "Vehicle Stability Enhancement Mode";
BA_ "GenSigLongName" SG_ 381 VSEStsHSC2 "Vehicle Stability Enhancement Status";
BA_ "GenSigLongName" SG_ 851 VehSpdAvgDrvnHSC2 "Vehicle Speed Average Driven";
BA_ "GenSigLongName" SG_ 851 VehSpdAvgDrvnVHSC2 "Vehicle Speed Average Driven Validity";
BA_ "GenSigLongName" SG_ 851 VehSpdAvgNonDrvnHSC2 "Vehicle Speed Average Non Driven";
BA_ "GenSigLongName" SG_ 851 VehSpdAvgNonDrvnVHSC2 "Vehicle Speed Average Non Driven Validity";
BA_ "GenSigLongName" SG_ 572 VehSpdAvgHSC2 "Vehicle Speed Average";
BA_ "GenSigLongName" SG_ 572 VehSpdAvgAlvRCHSC2 "Vehicle Speed Average Alive Rolling Count";
BA_ "GenSigLongName" SG_ 572 VehSpdAvgPVHSC2 "Vehicle Speed Average Protection Value";
BA_ "GenSigLongName" SG_ 572 VehSpdAvgVHSC2 "Vehicle Speed Average Validiy";
BA_ "GenSigStartValue" SG_ 588 LDrvnWhlRotlDircnHSC2 3;
BA_ "GenSigStartValue" SG_ 588 RDrvnWhlRotlDircnHSC2 3;
BA_ "GenSigLongName" SG_ 201 AccelActuPosHSC2 "Accelerator Actual Position";
BA_ "GenSigLongName" SG_ 201 AccelActuPosVHSC2 "Accelerator Actual Position Validity";
BA_ "GenSigLongName" SG_ 201 En12VoltStrMotCmddOnHSC2 "Engine 12 Volt Starter Motor Commanded On";
BA_ "GenSigLongName" SG_ 201 EnRunAHSC2 "Engine Run Active";
BA_ "GenSigLongName" SG_ 201 EnSpdHSC2 "Engine Speed";
BA_ "GenSigLongName" SG_ 201 PtBrkPdlDscrtInptStsHSC2 "Powertrain Brake Pedal Discrete Input Status";
BA_ "GenSigLongName" SG_ 201 PtBrkPdlDscrtInptStsVHSC2 "Powertrain Brake Pedal Discrete Input Status Validity";
BA_ "GenSigLongName" SG_ 190 AccelEfctvPosHSC2 "Accelerator Effective Position";
BA_ "GenSigLongName" SG_ 471 EnASSStaHSC2 "Engine Auto Stop Start State";
VAL_ 358 FVCMBlkdHSC2 1 "True" 0 "False" ;
VAL_ 358 FVCMFltStsHSC2 3 "Reserved" 2 "Reserved" 1 "Fault" 0 "No Fault" ;
VAL_ 358 LDWAdoWrnngDspCmdHSC2 3 "reserved" 2 "on" 1 "off" 0 "Unavailable" ;
VAL_ 358 LDWSnstvtLvlHSC2 3 "High" 2 "Standard" 1 "Low" 0 "unavailable" ;
VAL_ 358 LDWSysStsHSC2 7 "reserved" 6 "reserved" 5 "system temporary unavailable" 4 "service required" 3 "Override" 2 "Active" 1 "Stand by" 0 "Off" ;
VAL_ 359 AutoMainBeamLghtReqHSC2 3 "cannot detected the environment" 2 "Request  OFF  from camera" 1 "Request  ON from camera" 0 "No Request" ;
VAL_ 359 FVCMCalPrgsReqHSC2 7 "reserved" 6 "calibration failed" 5 "100%(Calibration Finished)" 4 "75% (Calibration in progress)" 3 "50% (Calibration in progress)" 2 "25%(Calibration in progress)" 1 "0% (Calibration Started)" 0 "no request" ;
VAL_ 359 HandOffStrgWhlDetnStaHSC2 3 "Hands Off(level 3)" 2 "Hands Off(level 2)" 1 "Hands On" 0 "Hands Off(level 1)" ;
VAL_ 359 HandOffStrgWhlDetnStaVHSC2 1 "Invalid" 0 "Valid" ;
VAL_ 359 LDWLKAAudReqHSC2 3 "Level 3" 2 "Level 2" 1 "Level 1" 0 "no request" ;
VAL_ 359 LDWLKADspCmdHSC2 7 "reserved" 6 "reserved" 5 "reserved" 4 "LKA" 3 "LDP(Include LDW warning)" 2 "LDW" 1 "off" 0 "Unavailable" ;
VAL_ 359 LDWLKAHapticWrnngDspCmdHSC2 3 "reserved" 2 "on" 1 "off" 0 "unavailable" ;
VAL_ 359 LDWLKALVsulznReqHSC2 7 "Reserved" 6 "Reserved" 5 "Reserved" 4 "intervention&warning" 3 "warning" 2 "intervention" 1 "line tracking" 0 "no display" ;
VAL_ 359 LDWLKARVsulznReqHSC2 7 "Reserved" 6 "Reserved" 5 "Reserved" 4 "intervention&warning" 3 "warning" 2 "intervention" 1 "line tracking" 0 "no display" ;
VAL_ 359 LDWSysFltStsHSC2 7 "Reserved" 6 "Reserved" 5 "Reserved" 4 "Reserved" 3 "service required" 2 "system temporary unavailable" 1 "performance degradation" 0 "no error" ;
VAL_ 359 SpdAstCondStsCamrHSC2 1 "conditional speed limit" 0 "non-conditional speed limit" ;
VAL_ 359 SpdAstReqStsCamrHSC2 2 "Active" 1 "Undefined" 0 "Fault" ;
VAL_ 359 TJAICADspCmdHSC2 3 "reserved" 2 "on" 1 "off" 0 "unavailable" ;
VAL_ 359 TJAICASysFltStsHSC2 7 "Reserved" 6 "Reserved" 5 "Reserved" 4 "Reserved" 3 "service required" 2 "system temporary unavailable" 1 "performance degradation" 0 "no error" ;
VAL_ 359 TJAICASysStsHSC2 7 "reserved" 6 "reserved" 5 "reserved" 4 "reserved" 3 "Override" 2 "Active" 1 "Stand by" 0 "Off" ;
VAL_ 509 LDWLKAVbnLvlReqHSC2 3 "Level 3" 2 "Level 2" 1 "Level 1" 0 "no request" ;
VAL_ 509 LKAAdoWrnngDspCmdHSC2 3 "reserved" 2 "on" 1 "off" 0 "unavailable" ;
VAL_ 509 LKADrvrTkovReqHSC2 1 "True" 0 "False" ;
VAL_ 509 LKAReqToqStsHSC2 3 "reserved" 2 "reserved" 1 "torque request" 0 "no request" ;
VAL_ 509 LKAReqToqVHSC2 1 "Invalid" 0 "Valid" ;
VAL_ 509 LKASysFltStsHSC2 3 "service required" 2 "system temporary unavailable" 1 "performance degradation" 0 "no error" ;
VAL_ 509 LKASysStsHSC2 3 "Override" 2 "Active" 1 "Stand by" 0 "Off" ;
VAL_ 438 BrkPdlAppdHSC2 1 "brake pedal applied" 0 "brake pedal not applied" ;
VAL_ 438 BrkPdlAppdVHSC2 2 "Faulty" 1 "Normal" 0 " Init" ;
VAL_ 492 ChLKACtrlStsHSC2 7 "reserved" 6 "reserved" 5 "reserved" 4 "pre-condition not satisfied" 3 "control not allowed for failure" 2 "lost arbitration" 1 "Request honored" 0 "No request" ;
VAL_ 492 ChLKARespToqVHSC2 1 "Invalid" 0 "Valid" ;
VAL_ 492 DrvrStrgDlvrdToqVHSC2 1 "Invalid" 0 "Valid" ;
VAL_ 492 StrgCustSetngDspCmdHSC2 3 "Sport Mode" 2 "Normal Mode" 1 "Comfortable Mode" 0 "Reserved" ;
VAL_ 1130 DipdBeamLghtOnHSC2 1 "True" 0 "False" ;
VAL_ 1130 DircnIndLampSwStsHSC2 3 "reserve" 2 "Right on" 1 "Left on" 0 "off" ;
VAL_ 1130 DspMeasSysHSC2 1 "mph" 0 "kph" ;
VAL_ 1130 FrtFogLghtOnHSC2 1 "True" 0 "False" ;
VAL_ 1130 FrtWiperParkPosAHSC2 1 "True" 0 "False" ;
VAL_ 1130 FrtWshrPumpAHSC2 1 "True" 0 "False" ;
VAL_ 1130 LDircnIndLghtFHSC2 1 "True" 0 "False" ;
VAL_ 1130 LDircnIOHSC2 1 "True" 0 "False" ;
VAL_ 1130 MainBeamLghtOnHSC2 1 "True" 0 "False" ;
VAL_ 1130 RDircnIndLghtFHSC2 1 "True" 0 "False" ;
VAL_ 1130 RDircnIOHSC2 1 "True" 0 "False" ;
VAL_ 1130 RrFogLghtOnHSC2 1 "True" 0 "False" ;
VAL_ 1130 VehSideLghtStsHSC2 3 "All side light and license plate light on" 2 "Right side light on only" 1 "Left side light on only" 0 "No side light on " ;
VAL_ 540 ClstrDspdVehSpdHSC2 255 "Speed Signal Missing Error of SCS" ;
VAL_ 540 FrtWiperSwStsHSC2 3 "wipers in fast mode" 2 "wipers in slow mode" 1 "wipers in intermittent mode" 0 "wipers off" ;
VAL_ 498 SysBPMHSC2 3 "Crank Request" 2 "Run" 1 "ACC" 0 "Off" ;
VAL_ 498 SysBPMEnbdHSC2 1 "True" 0 "False" ;
VAL_ 404 TrEstdGearHSC2 15 "Park Gear" 14 "Reverse Gear" 13 "Neutral Gear" 8 "Eighth Gear" 7 "Seventh Gear" 6 "Sixth Gear" 5 "Fifth Gear" 4 "Fourth Gear" 3 "Third Gear" 2 "Second Gear" 1 "First Gear" 0 "Not Supported" ;
VAL_ 404 TrEstdGearVHSC2 1 "Invalid" 0 "Valid" ;
VAL_ 404 TrShftLvrPosV_h1HSC2 1 "Invalid" 0 "Valid" ;
VAL_ 404 TrShftLvrPos_h1HSC2 15 "Lever Position Unknown" 11 "Forward Range H" 10 "Forward Range G" 9 "Forward Range F" 8 "Forward Range E" 7 "Forward Range D" 6 "Forward Range C" 5 "Forward Range B" 4 "Forward Range A" 3 "Neutral Range" 2 "Reverse Range" 1 "Park Range" 0 "Between Ranges" ;
VAL_ 251 SpdAstMdECMHSC2 3 "ISA" 2 "MSA" 1 "SLIF" 0 "Off" ;
VAL_ 251 SpdAstSysStsECMHSC2 7 "Reserved" 6 "Active (Passive)" 5 "Fault" 4 "Overspeed" 3 "Entry Conditions Incorrect" 2 "Standby" 1 "Active (Limiting)" 0 "Off" ;
VAL_ 251 TrgtSpdSrcStsHSC2 3 "Fault" 2 "Navigation" 1 "Camera" 0 "Undefined" ;
VAL_ 886 LDWLKASwReqHSC2 7 "Reserved" 6 "Reserved" 5 "Reserved" 4 "LKA" 3 "LDP" 2 "LDW" 1 "off" 0 "no request" ;
VAL_ 886 RstrFctryDeftsReqHSC2 1 "True" 0 "False" ;
VAL_ 758 LDWAdoWrnngReqHSC2 3 "reserved" 2 "on" 1 "off" 0 "no request" ;
VAL_ 758 LDWLKAHapticWrnngReqHSC2 3 "reserved" 2 "on" 1 "off" 0 "no request" ;
VAL_ 758 LDWSnstvtLvlReqHSC2 3 "High" 2 "Standard" 1 "Low" 0 "no request" ;
VAL_ 758 TJAICASwReqHSC2 3 "reserved" 2 "on" 1 "off" 0 "no request" ;
VAL_ 361 BCMAvlbly_h2HSC2 1 "True" 0 "False" ;
VAL_ 361 ECMAvlbly_h2HSC2 1 "True" 0 "False" ;
VAL_ 361 FICMAvlbly_h2HSC2 1 "True" 0 "False" ;
VAL_ 361 HCUAvlbly_h2HSC2 1 "True" 0 "False" ;
VAL_ 361 IPCAvlbly_h2HSC2 1 "True" 0 "False" ;
VAL_ 361 SDMAvlbly_h2HSC2 1 "True" 0 "False" ;
VAL_ 361 TBOXAvlbly_h2HSC2 1 "True" 0 "False" ;
VAL_ 361 TCMAvlbly_h2HSC2 1 "True" 0 "False" ;
VAL_ 497 BPMMstrAvlbly_h2HSC2 1 "True" 0 "False" ;
VAL_ 497 PwrMdMstrAccryA_h2HSC2 1 "Active" 0 "Inactive" ;
VAL_ 497 PwrMdMstrRunCrkA_h2HSC2 1 "Active" 0 "Inactive" ;
VAL_ 497 SysOpnlMd_h2HSC2 5 "Diagnosic or Reprogramming(Reserve)" 4 "Storage Mode" 3 "Show Room(Reserve)" 2 "Transit Mode" 1 "Manufacturing Mode" 0 "Normal Mode" ;
VAL_ 497 SysPwrMd_h2HSC2 3 "Crank Request" 2 "Run" 1 "Accessory" 0 "Off" ;
VAL_ 497 SysVolMdV_h2HSC2 1 "Invalid" 0 "Valid" ;
VAL_ 497 SysVolMd_h2HSC2 3 "Illegal System  Voltage" 2 "High System Voltage" 1 "Low System Voltage" 0 "Normal" ;
VAL_ 497 SysVolV_h2HSC2 1 "Invalid" 0 "Valid" ;
VAL_ 1344 VehOdoV_h2HSC2 1 "Invalid" 0 "Valid" ;
VAL_ 795 LKASwAHSC2 3 "Reserved" 2 "Failure Detected" 1 "Active" 0 "Inactive" ;
VAL_ 795 VehDrvngMd_h2HSC2 7 "Customization Mode" 6 "Reserved" 5 "Super Sport" 4 "Sport" 3 "Normal" 2 "ECO" 1 "Super ECO" 0 "No Driving Mode" ;
VAL_ 1009 OtsdAirTemCrValV_h2HSC2 1 "Invalid" 0 "Valid" ;
VAL_ 175 EPTAccelActuPosVHSC2 1 "Invalid" 0 "Valid" ;
VAL_ 175 EPTBrkPdlDscrtInptStsHSC2 1 "Brake Applied" 0 "Brake Not Applied" ;
VAL_ 175 EPTBrkPdlDscrtInptStsVHSC2 1 "Invalid" 0 "Valid" ;
VAL_ 175 EPTStCmdOn_h1HSC2 1 "True" 0 "False" ;
VAL_ 406 EPTRdy_h1HSC2 1 "Ready" 0 "Not ready" ;
VAL_ 172 SLIFStsHSC2 4 "Fault" 3 "Standby" 2 "Overspeed" 1 "Active" 0 "Off" ;
VAL_ 1345 CalendarMonthHSC2 12 "December" 11 "November" 10 "October" 9 "September" 8 "August" 7 "July" 6 "June" 5 "May" 4 "April" 3 "March" 2 "February" 1 "January" 0 "Unknown" ;
VAL_ 355 AirbagDplHSC2 1 "True" 0 "False" ;
VAL_ 355 AirbagDplInvsnHSC2 1 "No Airbag Deployed" 0 "Airbag Deployed" ;
VAL_ 355 DrvrSbltAtcHSC2 1 "True" 0 "False" ;
VAL_ 355 DrvrSbltAtcVHSC2 1 "Invalid" 0 "Valid" ;
VAL_ 485 StrgWhlAngHSC2 65535 "error mark" ;
VAL_ 485 StrgWhlAngGrdHSC2 4095 "error mark" ;
VAL_ 485 StrgWhlAngSnsrCalStsHSC2 3 "Unknown" 2 "Calibrated" 1 "Estimated" 0 "Unknown" ;
VAL_ 485 StrgWhlAngSnsrFltHSC2 1 "True" 0 "False" ;
VAL_ 485 StrgWhlAngSnsrInidHSC2 1 "True" 0 "False" ;
VAL_ 485 StrgWhlAngSnsrMultCapbHSC2 1 "True" 0 "False" ;
VAL_ 485 StrgWhlAngVHSC2 1 "Invalid" 0 "Valid" ;
VAL_ 389 VSELatAccVHSC2 1 "Invalid" 0 "Valid" ;
VAL_ 389 VSELongtAccVHSC2 1 "Invalid" 0 "Valid" ;
VAL_ 455 LNonDrvnWhlRotlDircnHSC2 3 "Error/Invalid" 2 "Moving backward" 1 "Moving forward" 0 "No moving" ;
VAL_ 455 RNonDrvnWhlRotlDircnHSC2 3 "Error/Invalid" 2 "Moving backward" 1 "Moving forward" 0 "No moving" ;
VAL_ 489 ABSAHSC2 1 "True" 0 "False" ;
VAL_ 489 ABSFHSC2 1 "True" 0 "False" ;
VAL_ 489 TCSAHSC2 1 "True" 0 "False" ;
VAL_ 489 VehDynYawRateVHSC2 1 "Invalid" 0 "Valid" ;
VAL_ 489 VSESysAHSC2 1 "True" 0 "False" ;
VAL_ 532 BrkPdlDrvrAppdPrsVHSC2 1 "Invalid" 0 "Valid" ;
VAL_ 840 WhlGndVelLDrvnVHSC2 1 "Invalid" 0 "Valid" ;
VAL_ 840 WhlGndVelRDrvnVHSC2 1 "Invalid" 0 "Valid" ;
VAL_ 842 WhlGndVelLNonDrvnVHSC2 1 "Invalid" 0 "Valid" ;
VAL_ 842 WhlGndVelRNonDrvnVHSC2 1 "Invalid" 0 "Valid" ;
VAL_ 381 TCSOpngMdHSC2 2 "Off Road" 1 "Normal" 0 "Off" ;
VAL_ 381 TCSOpngStsHSC2 2 "Fault" 1 "Active" 0 "Inactive" ;
VAL_ 381 VSEMdHSC2 2 "Competitive" 1 "Normal" 0 "Off" ;
VAL_ 381 VSEStsHSC2 4 "Not Ready" 3 "Warming Up" 2 "Fault" 1 "Active" 0 "Inactive" ;
VAL_ 851 VehSpdAvgDrvnVHSC2 1 "Invalid" 0 "Valid" ;
VAL_ 851 VehSpdAvgNonDrvnVHSC2 1 "Invalid" 0 "Valid" ;
VAL_ 572 VehSpdAvgVHSC2 1 "Invalid" 0 "Valid" ;
VAL_ 588 LDrvnWhlRotlDircnHSC2 3 "Initial/Invalid" 2 "Backward" 1 "Forward" 0 "Unknown" ;
VAL_ 588 RDrvnWhlRotlDircnHSC2 3 "Initial/Invalid" 2 "Backward" 1 "Forward" 0 "Unknown" ;
VAL_ 201 AccelActuPosVHSC2 1 "Invalid" 0 "Valid" ;
VAL_ 201 En12VoltStrMotCmddOnHSC2 1 "True" 0 "False" ;
VAL_ 201 EnRunAHSC2 1 "True" 0 "False" ;
VAL_ 201 PtBrkPdlDscrtInptStsHSC2 1 "Brake Applied" 0 "Brake Not Applied" ;
VAL_ 201 PtBrkPdlDscrtInptStsVHSC2 1 "Invalid" 0 "Valid" ;
VAL_ 471 EnASSStaHSC2 3 "Engine Stopping" 2 "Engine Starting" 1 "Engine Running" 0 "Engine Off" ;
